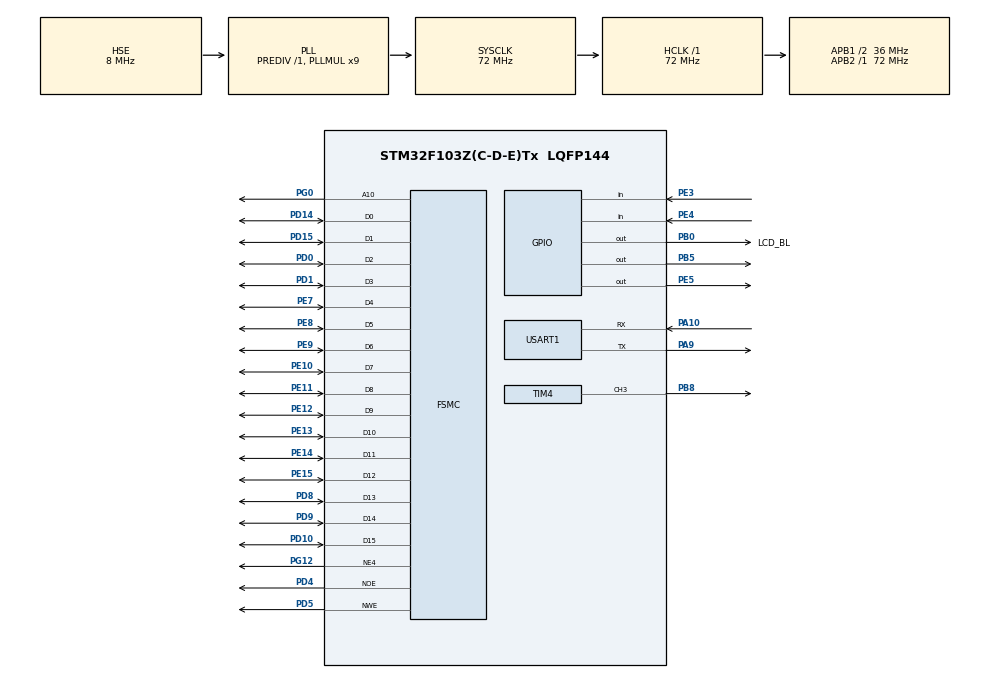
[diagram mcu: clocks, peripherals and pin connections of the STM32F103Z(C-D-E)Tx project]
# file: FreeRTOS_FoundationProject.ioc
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FREERTOS.Tasks01=defaultTask,24,128,StartDefaultTask,Default,NULL,Dynamic,NULL,NULL
FSMC.AddressSetupTime4=2
FSMC.BusTurnAroundDuration4=0
FSMC.DataSetupTime4=16
FSMC.ExtendedAddressSetupTime4=4
FSMC.ExtendedBusTurnAroundDuration4=0
FSMC.ExtendedDataSetupTime4=9
FSMC.ExtendedMode4=FSMC_EXTENDED_MODE_ENABLE
Mcu.Family=STM32F1
Mcu.Name=STM32F103Z(C-D-E)Tx
Mcu.Package=LQFP144
NVIC.PriorityGroup=NVIC_PRIORITYGROUP_4
NVIC.TIM5_IRQn=true\:15\:0\:false\:false\:true\:false\:false\:true\:true
NVIC.TimeBase=TIM5_IRQn
NVIC.TimeBaseIP=TIM5
NVIC.USART1_IRQn=true\:6\:0\:true\:false\:true\:true\:true\:true\:true
OSC_IN.Mode=HSE-External-Oscillator
OSC_IN.Signal=RCC_OSC_IN
OSC_OUT.Mode=HSE-External-Oscillator
OSC_OUT.Signal=RCC_OSC_OUT
PA0-WKUP.Mode=SYS_WakeUp0
PA0-WKUP.Signal=SYS_WKUP
PA10.Mode=Asynchronous
PA10.Signal=USART1_RX
PA13.Mode=Serial_Wire
PA13.Signal=SYS_JTMS-SWDIO
PA14.Mode=Serial_Wire
PA14.Signal=SYS_JTCK-SWCLK
PA9.Mode=Asynchronous
PA9.Signal=USART1_TX
PB0.GPIO_Label=LCD_BL
PB0.GPIO_PuPd=GPIO_PULLDOWN
PB0.Signal=GPIO_Output
PB5.GPIO_Speed=GPIO_SPEED_FREQ_LOW
PB5.PinState=GPIO_PIN_SET
PB5.Signal=GPIO_Output
PB8.Signal=S_TIM4_CH3
PD0.Signal=FSMC_D2_DA2
PD1.Signal=FSMC_D3_DA3
PD10.Signal=FSMC_D15_DA15
PD14.Signal=FSMC_D0_DA0
PD15.Signal=FSMC_D1_DA1
PD4.Signal=FSMC_NOE
PD5.Signal=FSMC_NWE
PD8.Signal=FSMC_D13_DA13
PD9.Signal=FSMC_D14_DA14
PE10.Signal=FSMC_D7_DA7
PE11.Signal=FSMC_D8_DA8
PE12.Signal=FSMC_D9_DA9
PE13.Signal=FSMC_D10_DA10
PE14.Signal=FSMC_D11_DA11
PE15.Signal=FSMC_D12_DA12
PE3.GPIO_PuPd=GPIO_PULLUP
PE3.Signal=GPIO_Input
PE4.GPIO_PuPd=GPIO_PULLUP
PE4.Signal=GPIO_Input
PE5.PinState=GPIO_PIN_SET
PE5.Signal=GPIO_Output
PE7.Signal=FSMC_D4_DA4
PE8.Signal=FSMC_D5_DA5
PE9.Signal=FSMC_D6_DA6
PG0.Signal=FSMC_A10
PG12.Mode=NorPsramChipSelect4_4
PG12.Signal=FSMC_NE4
ProjectManager.HeapSize=0x200
ProjectManager.StackSize=0x400
ProjectManager.TargetToolchain=MDK-ARM V5.32
RCC.AHBFreq_Value=72000000
RCC.APB1CLKDivider=RCC_HCLK_DIV2
RCC.APB1Freq_Value=36000000
RCC.APB1TimFreq_Value=72000000
RCC.APB2Freq_Value=72000000
RCC.APB2TimFreq_Value=72000000
RCC.HCLKFreq_Value=72000000
RCC.PLLMUL=RCC_PLL_MUL9
RCC.PLLSourceVirtual=RCC_PLLSOURCE_HSE
RCC.SYSCLKFreq_VALUE=72000000
RCC.SYSCLKSource=RCC_SYSCLKSOURCE_PLLCLK
RCC.USBFreq_Value=72000000
SH.FSMC_A10.0=FSMC_A10,A10_4
SH.FSMC_D0_DA0.0=FSMC_D0,16b-d4
SH.FSMC_D10_DA10.0=FSMC_D10,16b-d4
SH.FSMC_D11_DA11.0=FSMC_D11,16b-d4
SH.FSMC_D12_DA12.0=FSMC_D12,16b-d4
SH.FSMC_D13_DA13.0=FSMC_D13,16b-d4
SH.FSMC_D14_DA14.0=FSMC_D14,16b-d4
SH.FSMC_D15_DA15.0=FSMC_D15,16b-d4
SH.FSMC_D1_DA1.0=FSMC_D1,16b-d4
SH.FSMC_D2_DA2.0=FSMC_D2,16b-d4
SH.FSMC_D3_DA3.0=FSMC_D3,16b-d4
SH.FSMC_D4_DA4.0=FSMC_D4,16b-d4
SH.FSMC_D5_DA5.0=FSMC_D5,16b-d4
SH.FSMC_D6_DA6.0=FSMC_D6,16b-d4
SH.FSMC_D7_DA7.0=FSMC_D7,16b-d4
SH.FSMC_D8_DA8.0=FSMC_D8,16b-d4
SH.FSMC_D9_DA9.0=FSMC_D9,16b-d4
SH.FSMC_NOE.0=FSMC_NOE,Lcd4
SH.FSMC_NWE.0=FSMC_NWE,Lcd4
SH.S_TIM4_CH3.0=TIM4_CH3,PWM Generation3 CH3
TIM4.AutoReloadPreload=TIM_AUTORELOAD_PRELOAD_ENABLE
TIM4.Channel-PWM\ Generation3\ CH3=TIM_CHANNEL_3
TIM4.Period=999
TIM4.Prescaler=71
TIM4.Pulse-PWM\ Generation3\ CH3=499
USART1.VirtualMode=VM_ASYNC
VP_FREERTOS_VS_CMSIS_V2.Mode=CMSIS_V2
VP_SYS_VS_tim5.Mode=TIM5
VP_TIM4_VS_ClockSourceINT.Mode=Internal
board=custom

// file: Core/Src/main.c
/* USER CODE BEGIN Header */
/**
  ******************************************************************************
  * @file           : main.c
  * @brief          : Main program body
  ******************************************************************************
  * @attention
  *
  * Copyright (c) 2024 STMicroelectronics.
  * All rights reserved.
  *
  * This software is licensed under terms that can be found in the LICENSE file
  * in the root directory of this software component.
  * If no LICENSE file comes with this software, it is provided AS-IS.
  *
  ******************************************************************************
  */
/* USER CODE END Header */
#include "main.h"
#include "cmsis_os.h"
#include "tim.h"
#include "usart.h"
#include "gpio.h"
#include "fsmc.h"

void SystemClock_Config(void);
void MX_FREERTOS_Init(void);

int main(void)
{

  /* MCU Configuration--------------------------------------------------------*/

  /* Reset of all peripherals, Initializes the Flash interface and the Systick. */
  HAL_Init();

  /* Configure the system clock */
  SystemClock_Config();

  /* Initialize all configured peripherals */
  MX_GPIO_Init();
  MX_TIM4_Init();
  MX_FSMC_Init();
  MX_USART1_UART_Init();
  /* USER CODE BEGIN 2 */

	printf("STM32F103xx Ready!!!\r\n");

  /* USER CODE END Init */
  /* USER CODE END 2 */

  /* Init scheduler */
  osKernelInitialize();

  /* Call init function for freertos objects (in freertos.c) */
  MX_FREERTOS_Init();

  /* Start scheduler */
  osKernelStart();

  /* We should never get here as control is now taken by the scheduler */
  /* Infinite loop */
  while (1)
  {

  }
}

void SystemClock_Config(void)
{
  RCC_OscInitTypeDef RCC_OscInitStruct = {0};
  RCC_ClkInitTypeDef RCC_ClkInitStruct = {0};

  /** Initializes the RCC Oscillators according to the specified parameters
  * in the RCC_OscInitTypeDef structure.
  */
  RCC_OscInitStruct.OscillatorType = RCC_OSCILLATORTYPE_HSE;
  RCC_OscInitStruct.HSEState = RCC_HSE_ON;
  RCC_OscInitStruct.HSEPredivValue = RCC_HSE_PREDIV_DIV1;
  RCC_OscInitStruct.HSIState = RCC_HSI_ON;
  RCC_OscInitStruct.PLL.PLLState = RCC_PLL_ON;
  RCC_OscInitStruct.PLL.PLLSource = RCC_PLLSOURCE_HSE;
  RCC_OscInitStruct.PLL.PLLMUL = RCC_PLL_MUL9;
  if (HAL_RCC_OscConfig(&RCC_OscInitStruct) != HAL_OK)
  {
    Error_Handler();
  }

  /** Initializes the CPU, AHB and APB buses clocks
  */
  RCC_ClkInitStruct.ClockType = RCC_CLOCKTYPE_HCLK|RCC_CLOCKTYPE_SYSCLK
                              |RCC_CLOCKTYPE_PCLK1|RCC_CLOCKTYPE_PCLK2;
  RCC_ClkInitStruct.SYSCLKSource = RCC_SYSCLKSOURCE_PLLCLK;
  RCC_ClkInitStruct.AHBCLKDivider = RCC_SYSCLK_DIV1;
  RCC_ClkInitStruct.APB1CLKDivider = RCC_HCLK_DIV2;
  RCC_ClkInitStruct.APB2CLKDivider = RCC_HCLK_DIV1;

  if (HAL_RCC_ClockConfig(&RCC_ClkInitStruct, FLASH_LATENCY_2) != HAL_OK)
  {
    Error_Handler();
  }
}

void HAL_TIM_PeriodElapsedCallback(TIM_HandleTypeDef *htim)
{
  if (htim->Instance == TIM5) {
    HAL_IncTick();
  }
}

void Error_Handler(void)
{
  __disable_irq();
  while (1)
  {
  }
}

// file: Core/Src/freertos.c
/* USER CODE BEGIN Header */
/**
  ******************************************************************************
  * File Name          : freertos.c
  * Description        : Code for freertos applications
  ******************************************************************************
  * @attention
  *
  * Copyright (c) 2024 STMicroelectronics.
  * All rights reserved.
  *
  * This software is licensed under terms that can be found in the LICENSE file
  * in the root directory of this software component.
  * If no LICENSE file comes with this software, it is provided AS-IS.
  *
  ******************************************************************************
  */
/* USER CODE END Header */

#include "FreeRTOS.h"
#include "task.h"
#include "main.h"
#include "cmsis_os.h"

/* Definitions for defaultTask */
osThreadId_t defaultTaskHandle;
const osThreadAttr_t defaultTask_attributes = {
  .name = "defaultTask",
  .stack_size = 128 * 4,
  .priority = (osPriority_t) osPriorityNormal,
};

void StartDefaultTask(void *argument);

void MX_FREERTOS_Init(void); /* (MISRA C 2004 rule 8.1) */

void MX_FREERTOS_Init(void) {
  /* USER CODE BEGIN Init */
	FreeRTOS_Dynamic_Demo(NULL);
  /* USER CODE END Init */

  /* USER CODE BEGIN RTOS_SEMAPHORES */
  /* add semaphores, ... */
			// xTaskBase_Dynamic_KEY = xTaskCreate(KEY_test,"KEYtask",128,NULL,3,xTaskHandle_Dynamic_KEY);
  /* USER CODE END RTOS_SEMAPHORES */

  /* Create the thread(s) */
  /* creation of defaultTask */
  defaultTaskHandle = osThreadNew(StartDefaultTask, NULL, &defaultTask_attributes);

}

void StartDefaultTask(void *argument)
{
  for(;;)
  {
    osDelay(1);
  }
}
